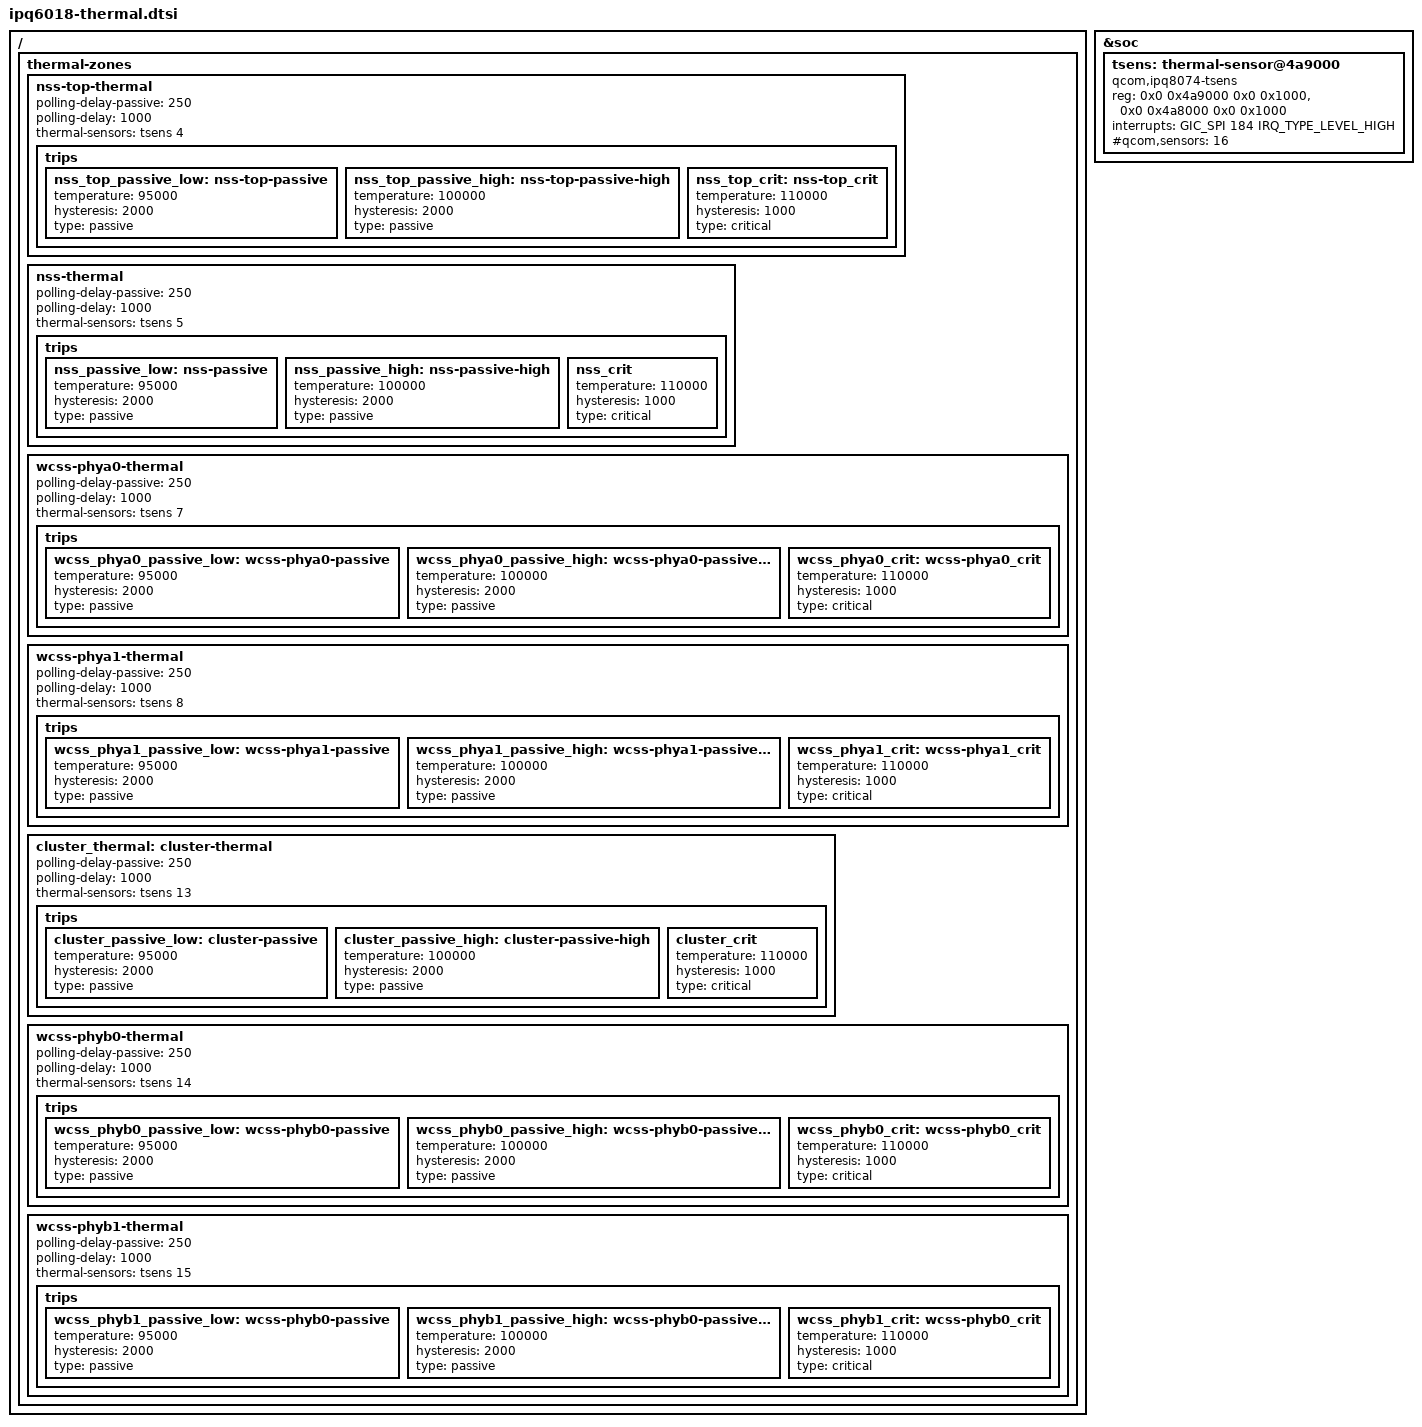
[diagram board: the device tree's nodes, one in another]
#include <dt-bindings/thermal/thermal.h>

/ {
	thermal-zones {
		nss-top-thermal {
			polling-delay-passive = <250>;
			polling-delay = <1000>;

			thermal-sensors = <&tsens 4>;

			trips {
				nss_top_passive_low: nss-top-passive {
					temperature = <95000>;
					hysteresis = <2000>;
					type = "passive";
				};

				nss_top_passive_high: nss-top-passive-high {
					temperature = <100000>;
					hysteresis = <2000>;
					type = "passive";
				};

				nss_top_crit: nss-top_crit {
					temperature = <110000>;
					hysteresis = <1000>;
					type = "critical";
				};
			};
		};

		nss-thermal {
			polling-delay-passive = <250>;
			polling-delay = <1000>;

			thermal-sensors = <&tsens 5>;

			trips {
				nss_passive_low: nss-passive {
					temperature = <95000>;
					hysteresis = <2000>;
					type = "passive";
				};

				nss_passive_high: nss-passive-high {
					temperature = <100000>;
					hysteresis = <2000>;
					type = "passive";
				};

				nss_crit: nss_crit {
					temperature = <110000>;
					hysteresis = <1000>;
					type = "critical";
				};
			};
		};

		wcss-phya0-thermal {
			polling-delay-passive = <250>;
			polling-delay = <1000>;

			thermal-sensors = <&tsens 7>;

			trips {
				wcss_phya0_passive_low: wcss-phya0-passive {
					temperature = <95000>;
					hysteresis = <2000>;
					type = "passive";
				};

				wcss_phya0_passive_high: wcss-phya0-passive-high {
					temperature = <100000>;
					hysteresis = <2000>;
					type = "passive";
				};

				wcss_phya0_crit: wcss-phya0_crit {
					temperature = <110000>;
					hysteresis = <1000>;
					type = "critical";
				};
			};
		};

		wcss-phya1-thermal {
			polling-delay-passive = <250>;
			polling-delay = <1000>;

			thermal-sensors = <&tsens 8>;

			trips {
				wcss_phya1_passive_low: wcss-phya1-passive {
					temperature = <95000>;
					hysteresis = <2000>;
					type = "passive";
				};

				wcss_phya1_passive_high: wcss-phya1-passive-high {
					temperature = <100000>;
					hysteresis = <2000>;
					type = "passive";
				};

				wcss_phya1_crit: wcss-phya1_crit {
					temperature = <110000>;
					hysteresis = <1000>;
					type = "critical";
				};
			};
		};

		cluster_thermal: cluster-thermal {
			polling-delay-passive = <250>;
			polling-delay = <1000>;

			thermal-sensors = <&tsens 13>;

			trips {
				cluster_passive_low: cluster-passive {
					temperature = <95000>;
					hysteresis = <2000>;
					type = "passive";
				};

				cluster_passive_high: cluster-passive-high {
					temperature = <100000>;
					hysteresis = <2000>;
					type = "passive";
				};

				cluster_crit: cluster_crit {
					temperature = <110000>;
					hysteresis = <1000>;
					type = "critical";
				};
			};
		};

		wcss-phyb0-thermal {
			polling-delay-passive = <250>;
			polling-delay = <1000>;

			thermal-sensors = <&tsens 14>;

			trips {
				wcss_phyb0_passive_low: wcss-phyb0-passive {
					temperature = <95000>;
					hysteresis = <2000>;
					type = "passive";
				};

				wcss_phyb0_passive_high: wcss-phyb0-passive-high {
					temperature = <100000>;
					hysteresis = <2000>;
					type = "passive";
				};

				wcss_phyb0_crit: wcss-phyb0_crit {
					temperature = <110000>;
					hysteresis = <1000>;
					type = "critical";
				};
			};
		};

		wcss-phyb1-thermal {
			polling-delay-passive = <250>;
			polling-delay = <1000>;

			thermal-sensors = <&tsens 15>;

			trips {
				wcss_phyb1_passive_low: wcss-phyb0-passive {
					temperature = <95000>;
					hysteresis = <2000>;
					type = "passive";
				};

				wcss_phyb1_passive_high: wcss-phyb0-passive-high {
					temperature = <100000>;
					hysteresis = <2000>;
					type = "passive";
				};

				wcss_phyb1_crit: wcss-phyb0_crit {
					temperature = <110000>;
					hysteresis = <1000>;
					type = "critical";
				};
			};
		};
	};
};

&soc {
	tsens: thermal-sensor@4a9000 {
		compatible = "qcom,ipq8074-tsens";
		reg = <0x0 0x4a9000 0x0 0x1000>, /* TM */
		      <0x0 0x4a8000 0x0 0x1000>; /* SROT */
		interrupts = <GIC_SPI 184 IRQ_TYPE_LEVEL_HIGH>;
		interrupt-names = "combined";
		#qcom,sensors = <16>;
		#thermal-sensor-cells = <1>;
  };
};
